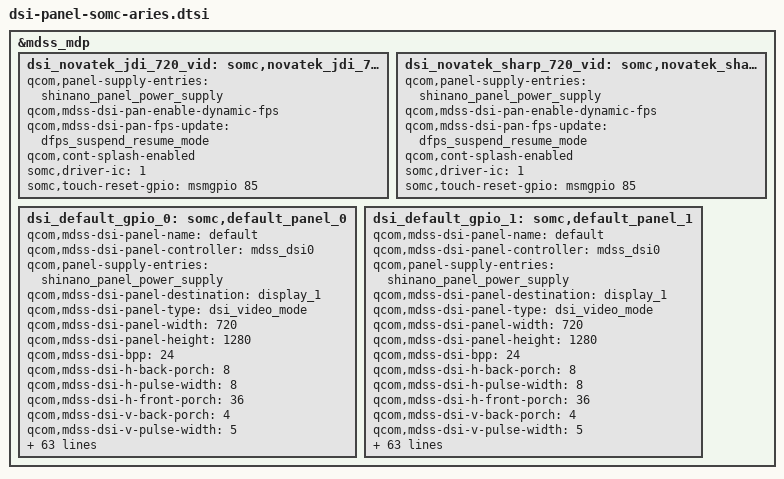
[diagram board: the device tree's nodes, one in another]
/* Copyright (c) 2013-2015, The Linux Foundation. All rights reserved.
 *
 * This program is free software; you can redistribute it and/or modify
 * it under the terms of the GNU General Public License version 2 and
 * only version 2 as published by the Free Software Foundation.
 *
 * This program is distributed in the hope that it will be useful,
 * but WITHOUT ANY WARRANTY; without even the implied warranty of
 * MERCHANTABILITY or FITNESS FOR A PARTICULAR PURPOSE.  See the
 * GNU General Public License for more details.
 */
/*
 * Copyright (C) 2015 Sony Mobile Communications Inc.
 *
 * This program is free software; you can redistribute it and/or modify
 * it under the terms of the GNU General Public License version 2, as
 * published by the Free Software Foundation.
 */

#include "dsi-panel-somc-novatek-jdi-720p-vid.dtsi"
#include "dsi-panel-somc-novatek-sharp-720p-vid.dtsi"

&mdss_mdp {
	dsi_novatek_jdi_720_vid: somc,novatek_jdi_720p_video_panel {
		qcom,panel-supply-entries = <&shinano_panel_power_supply>;
		qcom,mdss-dsi-pan-enable-dynamic-fps;
		qcom,mdss-dsi-pan-fps-update = "dfps_suspend_resume_mode";
		qcom,cont-splash-enabled;
		somc,driver-ic = <1>;
		somc,touch-reset-gpio = <&msmgpio 85 0>;
	};

	dsi_novatek_sharp_720_vid: somc,novatek_sharp_720p_video_panel {
		qcom,panel-supply-entries = <&shinano_panel_power_supply>;
		qcom,mdss-dsi-pan-enable-dynamic-fps;
		qcom,mdss-dsi-pan-fps-update = "dfps_suspend_resume_mode";
		qcom,cont-splash-enabled;
		somc,driver-ic = <1>;
		somc,touch-reset-gpio = <&msmgpio 85 0>;
	};

	dsi_default_gpio_0: somc,default_panel_0 {
		qcom,mdss-dsi-panel-name = "default";
		qcom,mdss-dsi-panel-controller = <&mdss_dsi0>;
		qcom,panel-supply-entries = <&shinano_panel_power_supply>;
		qcom,mdss-dsi-panel-destination = "display_1";
		qcom,mdss-dsi-panel-type = "dsi_video_mode";
		qcom,mdss-dsi-panel-width = <720>;
		qcom,mdss-dsi-panel-height = <1280>;
		qcom,mdss-dsi-bpp = <24>;
		qcom,mdss-dsi-h-back-porch = <8>;
		qcom,mdss-dsi-h-pulse-width = <8>;
		qcom,mdss-dsi-h-front-porch = <36>;
		qcom,mdss-dsi-v-back-porch = <4>;
		qcom,mdss-dsi-v-pulse-width = <5>;
		qcom,mdss-dsi-v-front-porch = <251>;
		qcom,mdss-pan-physical-width-dimension = <56>;
		qcom,mdss-pan-physical-height-dimension = <100>;
		qcom,mdss-dsi-panel-framerate = <60>;
		qcom,mdss-dsi-virtual-channel-id = <0>;
		qcom,mdss-dsi-stream = <0>;
		qcom,mdss-dsi-h-sync-skew = <0>;
		qcom,mdss-dsi-h-left-border = <0>;
		qcom,mdss-dsi-h-right-border = <0>;
		qcom,mdss-dsi-v-top-border = <0>;
		qcom,mdss-dsi-v-bottom-border = <0>;
		qcom,mdss-dsi-underflow-color = <0x0>;
		qcom,mdss-dsi-border-color = <0>;
		qcom,mdss-dsi-h-sync-pulse = <1>;
		qcom,mdss-dsi-traffic-mode = "non_burst_sync_event";
		qcom,mdss-dsi-bllp-eof-power-mode;
		qcom,mdss-dsi-bllp-power-mode;
		qcom,mdss-dsi-dma-trigger = "trigger_sw";
		qcom,mdss-dsi-mdp-trigger = "none";
		somc,mdss-dsi-early-init-command = [15 01 00 00 00 00 02 FF EE
				15 01 00 00 01 00 02 26 08
				15 01 00 00 00 00 02 26 00
				15 01 00 00 0A 00 02 FF 00];
		somc,mdss-dsi-init-command = [15 01 00 00 00 00 02 BA 03
				15 01 00 00 00 00 02 C2 08
				15 01 00 00 00 00 02 FB 01
				15 01 00 00 00 00 02 FF 05
				15 01 00 00 00 00 02 02 8E
				15 01 00 00 00 00 02 A2 00
				15 01 00 00 00 00 02 FB 01
				15 01 00 00 00 00 02 FF EE
				15 01 00 00 00 00 02 12 50
				15 01 00 00 00 00 02 13 02
				15 01 00 00 00 00 02 6A 60
				15 01 00 00 00 00 02 FB 01
				15 01 00 00 00 00 02 FF 00
				05 01 00 00 64 00 01 11
				15 01 00 00 00 00 02 35 00];
		qcom,mdss-dsi-reset-sequence = <1 20>, <0 200>, <1 20>;
		qcom,mdss-dsi-on-command = [05 01 00 00 00 00 01 29];
		qcom,mdss-dsi-off-command = [05 01 00 00 00 00 01 28
				05 01 00 00 64 00 01 10];
		qcom,mdss-dsi-on-command-state = "dsi_lp_mode";
		qcom,mdss-dsi-off-command-state = "dsi_hs_mode";

		qcom,mdss-dsi-lane-0-state;
		qcom,mdss-dsi-lane-1-state;
		qcom,mdss-dsi-lane-2-state;
		qcom,mdss-dsi-lane-3-state;
		qcom,mdss-dsi-panel-timings = [7A 1A 12 00 3E 42 16 20 14 03 04 00];
		qcom,mdss-dsi-t-clk-post = <0x11>;
		qcom,mdss-dsi-t-clk-pre = <0x1A>;
		qcom,mdss-dsi-lp11-init;
		qcom,mdss-dsi-bl-min-level = <1>;
		qcom,mdss-dsi-bl-max-level = <255>;
		qcom,mdss-brightness-max-level = <255>;
		qcom,mdss-dsi-bl-pmic-control-type = "bl_ctrl_wled";

		somc,mdss-dsi-disp-on-in-hs = <1>;
		somc,mdss-dsi-lane-config = [00 c2 ef 00 00 00 00 01 ff
				00 c2 ef 00 00 00 00 01 ff
				00 c2 ef 00 00 00 00 01 ff
				00 c2 ef 00 00 00 00 01 ff
				00 02 00 00 00 00 00 01 97];
		somc,disp-en-on-post = <20>;
		somc,pw-on-rst-seq = <0 1>, <1 20>;
		somc,disp-en-off-post = <0>;
		somc,pw-off-rst-b-seq = <0 10>;
		somc,pw-down-period = <200>;

		somc,lcd-id = <0>;
		somc,lcd-id-adc = <0 0x7fffffff>;

		qcom,mdss-dsi-pan-enable-dynamic-fps;
		qcom,mdss-dsi-pan-fps-update = "dfps_suspend_resume_mode";
		qcom,cont-splash-enabled;
		somc,driver-ic = <0>;
		somc,touch-reset-gpio = <&msmgpio 85 0>;
		somc,mdss-phy-size-mm = <56 100>;
	};

	dsi_default_gpio_1: somc,default_panel_1 {
		qcom,mdss-dsi-panel-name = "default";
		qcom,mdss-dsi-panel-controller = <&mdss_dsi0>;
		qcom,panel-supply-entries = <&shinano_panel_power_supply>;
		qcom,mdss-dsi-panel-destination = "display_1";
		qcom,mdss-dsi-panel-type = "dsi_video_mode";
		qcom,mdss-dsi-panel-width = <720>;
		qcom,mdss-dsi-panel-height = <1280>;
		qcom,mdss-dsi-bpp = <24>;
		qcom,mdss-dsi-h-back-porch = <8>;
		qcom,mdss-dsi-h-pulse-width = <8>;
		qcom,mdss-dsi-h-front-porch = <36>;
		qcom,mdss-dsi-v-back-porch = <4>;
		qcom,mdss-dsi-v-pulse-width = <5>;
		qcom,mdss-dsi-v-front-porch = <251>;
		qcom,mdss-pan-physical-width-dimension = <56>;
		qcom,mdss-pan-physical-height-dimension = <100>;
		qcom,mdss-dsi-panel-framerate = <60>;
		qcom,mdss-dsi-virtual-channel-id = <0>;
		qcom,mdss-dsi-stream = <0>;
		qcom,mdss-dsi-h-sync-skew = <0>;
		qcom,mdss-dsi-h-left-border = <0>;
		qcom,mdss-dsi-h-right-border = <0>;
		qcom,mdss-dsi-v-top-border = <0>;
		qcom,mdss-dsi-v-bottom-border = <0>;
		qcom,mdss-dsi-underflow-color = <0x0>;
		qcom,mdss-dsi-border-color = <0>;
		qcom,mdss-dsi-h-sync-pulse = <1>;
		qcom,mdss-dsi-traffic-mode = "non_burst_sync_event";
		qcom,mdss-dsi-bllp-eof-power-mode;
		qcom,mdss-dsi-bllp-power-mode;
		qcom,mdss-dsi-dma-trigger = "trigger_sw";
		qcom,mdss-dsi-mdp-trigger = "none";
		somc,mdss-dsi-early-init-command = [15 01 00 00 00 00 02 FF EE
				15 01 00 00 01 00 02 26 08
				15 01 00 00 00 00 02 26 00
				15 01 00 00 0A 00 02 FF 00];
		somc,mdss-dsi-init-command = [15 01 00 00 00 00 02 BA 03
				15 01 00 00 00 00 02 C2 08
				15 01 00 00 00 00 02 FB 01
				15 01 00 00 00 00 02 FF 05
				15 01 00 00 00 00 02 02 8E
				15 01 00 00 00 00 02 A2 00
				15 01 00 00 00 00 02 FB 01
				15 01 00 00 00 00 02 FF EE
				15 01 00 00 00 00 02 12 50
				15 01 00 00 00 00 02 13 02
				15 01 00 00 00 00 02 6A 60
				15 01 00 00 00 00 02 FB 01
				15 01 00 00 00 00 02 FF 00
				05 01 00 00 64 00 01 11
				15 01 00 00 00 00 02 35 00];
		qcom,mdss-dsi-reset-sequence = <1 20>, <0 200>, <1 20>;
		qcom,mdss-dsi-on-command = [05 01 00 00 00 00 01 29];
		qcom,mdss-dsi-off-command = [05 01 00 00 00 00 01 28
				05 01 00 00 64 00 01 10];
		qcom,mdss-dsi-on-command-state = "dsi_lp_mode";
		qcom,mdss-dsi-off-command-state = "dsi_hs_mode";

		qcom,mdss-dsi-lane-0-state;
		qcom,mdss-dsi-lane-1-state;
		qcom,mdss-dsi-lane-2-state;
		qcom,mdss-dsi-lane-3-state;
		qcom,mdss-dsi-panel-timings = [7A 1A 12 00 3E 42 16 20 14 03 04 00];
		qcom,mdss-dsi-t-clk-post = <0x11>;
		qcom,mdss-dsi-t-clk-pre = <0x1A>;
		qcom,mdss-dsi-lp11-init;
		qcom,mdss-dsi-bl-min-level = <1>;
		qcom,mdss-dsi-bl-max-level = <255>;
		qcom,mdss-brightness-max-level = <255>;
		qcom,mdss-dsi-bl-pmic-control-type = "bl_ctrl_wled";

		somc,mdss-dsi-disp-on-in-hs = <1>;
		somc,mdss-dsi-lane-config = [00 c2 ef 00 00 00 00 01 ff
				00 c2 ef 00 00 00 00 01 ff
				00 c2 ef 00 00 00 00 01 ff
				00 c2 ef 00 00 00 00 01 ff
				00 02 00 00 00 00 00 01 97];
		somc,disp-en-on-post = <20>;
		somc,pw-on-rst-seq = <0 1>, <1 20>;
		somc,disp-en-off-post = <0>;
		somc,pw-off-rst-b-seq = <0 10>;
		somc,pw-down-period = <200>;
		somc,lcd-id = <1>;
		somc,lcd-id-adc = <0 0x7fffffff>;

		qcom,mdss-dsi-pan-enable-dynamic-fps;
		qcom,mdss-dsi-pan-fps-update = "dfps_suspend_resume_mode";
		qcom,cont-splash-enabled;
		somc,driver-ic = <1>;
		somc,touch-reset-gpio = <&msmgpio 85 0>;
		somc,mdss-phy-size-mm = <56 100>;
	};
};
